# VPE_VPDMA register map
Vendor: Texas Instruments
Registers are 32-bit, access per field, reset 0x0 unless marked. A register's access mark holds for its fields unless they carry their own. Offsets are as the file gives them; [hi:lo] are bit positions; {n}, {i} and the like mark numbered series; 'fields as' and 'values as' point back to an identical list.

## VPE_VPDMA (part 3 of 3)
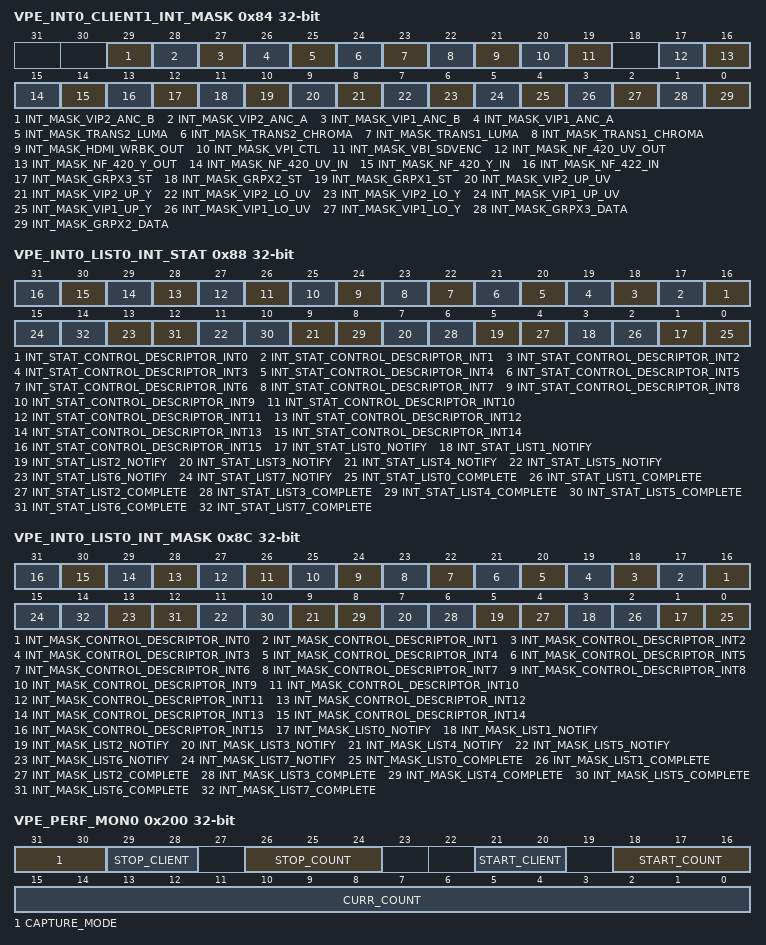
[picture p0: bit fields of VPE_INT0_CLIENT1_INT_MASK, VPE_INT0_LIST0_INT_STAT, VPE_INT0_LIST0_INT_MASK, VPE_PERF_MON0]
0x84 VPE_INT0_CLIENT1_INT_MASK — The register gives the information of the interrupts that should be masked and not generate an interrupt for vpdma_int0.
  [29] INT_MASK_VIP2_ANC_B rw — The interrupt for should generate an interrupt on interrupt vpdma_int0. Write a 1 for the interrupt event to trigger the interrupt signal.
  [28] INT_MASK_VIP2_ANC_A rw — The interrupt for should generate an interrupt on interrupt vpdma_int0. Write a 1 for the interrupt event to trigger the interrupt signal.
  [27] INT_MASK_VIP1_ANC_B rw — The interrupt for should generate an interrupt on interrupt vpdma_int0. Write a 1 for the interrupt event to trigger the interrupt signal.
  [26] INT_MASK_VIP1_ANC_A rw — The interrupt for should generate an interrupt on interrupt vpdma_int0. Write a 1 for the interrupt event to trigger the interrupt signal.
  [25] INT_MASK_TRANS2_LUMA rw — The interrupt for should generate an interrupt on interrupt vpdma_int0. Write a 1 for the interrupt event to trigger the interrupt signal.
  [24] INT_MASK_TRANS2_CHROMA rw — The interrupt for should generate an interrupt on interrupt vpdma_int0. Write a 1 for the interrupt event to trigger the interrupt signal.
  [23] INT_MASK_TRANS1_LUMA rw — The interrupt for should generate an interrupt on interrupt vpdma_int0. Write a 1 for the interrupt event to trigger the interrupt signal.
  [22] INT_MASK_TRANS1_CHROMA rw — The interrupt for should generate an interrupt on interrupt vpdma_int0. Write a 1 for the interrupt event to trigger the interrupt signal.
  [21] INT_MASK_HDMI_WRBK_OUT rw — The interrupt for should generate an interrupt on interrupt vpdma_int0. Write a 1 for the interrupt event to trigger the interrupt signal.
  [20] INT_MASK_VPI_CTL rw — The interrupt for should generate an interrupt on interrupt vpdma_int0. Write a 1 for the interrupt event to trigger the interrupt signal.
  [19] INT_MASK_VBI_SDVENC rw — The interrupt for should generate an interrupt on interrupt vpdma_int0. Write a 1 for the interrupt event to trigger the interrupt signal.
  [17] INT_MASK_NF_420_UV_OUT rw — The interrupt for should generate an interrupt on interrupt vpdma_int0. Write a 1 for the interrupt event to trigger the interrupt signal.
  [16] INT_MASK_NF_420_Y_OUT rw — The interrupt for should generate an interrupt on interrupt vpdma_int0. Write a 1 for the interrupt event to trigger the interrupt signal.
  [15] INT_MASK_NF_420_UV_IN rw — The interrupt for should generate an interrupt on interrupt vpdma_int0. Write a 1 for the interrupt event to trigger the interrupt signal.
  [14] INT_MASK_NF_420_Y_IN rw — The interrupt for should generate an interrupt on interrupt vpdma_int0. Write a 1 for the interrupt event to trigger the interrupt signal.
  [13] INT_MASK_NF_422_IN rw — The interrupt for should generate an interrupt on interrupt vpdma_int0. Write a 1 for the interrupt event to trigger the interrupt signal.
  [12] INT_MASK_GRPX3_ST rw — The interrupt for should generate an interrupt on interrupt vpdma_int0. Write a 1 for the interrupt event to trigger the interrupt signal.
  [11] INT_MASK_GRPX2_ST rw — The interrupt for should generate an interrupt on interrupt vpdma_int0. Write a 1 for the interrupt event to trigger the interrupt signal.
  [10] INT_MASK_GRPX1_ST rw — The interrupt for should generate an interrupt on interrupt vpdma_int0. Write a 1 for the interrupt event to trigger the interrupt signal.
  [9] INT_MASK_VIP2_UP_UV rw — The interrupt for should generate an interrupt on interrupt vpdma_int0. Write a 1 for the interrupt event to trigger the interrupt signal.
  [8] INT_MASK_VIP2_UP_Y rw — The interrupt for should generate an interrupt on interrupt vpdma_int0. Write a 1 for the interrupt event to trigger the interrupt signal.
  [7] INT_MASK_VIP2_LO_UV rw — The interrupt for should generate an interrupt on interrupt vpdma_int0. Write a 1 for the interrupt event to trigger the interrupt signal.
  [6] INT_MASK_VIP2_LO_Y rw — The interrupt for should generate an interrupt on interrupt vpdma_int0. Write a 1 for the interrupt event to trigger the interrupt signal.
  [5] INT_MASK_VIP1_UP_UV rw — The interrupt for should generate an interrupt on interrupt vpdma_int0. Write a 1 for the interrupt event to trigger the interrupt signal.
  [4] INT_MASK_VIP1_UP_Y rw — The interrupt for should generate an interrupt on interrupt vpdma_int0. Write a 1 for the interrupt event to trigger the interrupt signal.
  [3] INT_MASK_VIP1_LO_UV rw — The interrupt for should generate an interrupt on interrupt vpdma_int0. Write a 1 for the interrupt event to trigger the interrupt signal.
  [2] INT_MASK_VIP1_LO_Y rw — The interrupt for should generate an interrupt on interrupt vpdma_int0. Write a 1 for the interrupt event to trigger the interrupt signal.
  [1] INT_MASK_GRPX3_DATA rw — The interrupt for should generate an interrupt on interrupt vpdma_int0. Write a 1 for the interrupt event to trigger the interrupt signal.
  [0] INT_MASK_GRPX2_DATA rw — The interrupt for should generate an interrupt on interrupt vpdma_int0. Write a 1 for the interrupt event to trigger the interrupt signal.
0x88 VPE_INT0_LIST0_INT_STAT rw — This register gives the information of the interrupts that have triggered since last cleared by the process that is servicing vpdma_int0.
  [n+16] INT_STAT_CONTROL_DESCRIPTOR_INT{n} (n=0..15) — A Send Interrupt Control Descriptor has been received by the list manager with a source value of {n}. This event will cause a one to be set in this register until cleared by software. Write a 1 to this field to clear the value.
  [2n+1] INT_STAT_LIST{n}_NOTIFY (n=0..7) — A channel set by List {n} has completed and the Notify bit had been set in the descriptor for that channel. This event will cause a one to be set in this register until cleared by software. Write a 1 to this field to clear the value.
  [2n] INT_STAT_LIST{n}_COMPLETE (n=0..7) — List {n} has completed and a new list can be loaded. This event will cause a one to be set in this register until cleared by software. Write a 1 to this field to clear the value.
0x8C VPE_INT0_LIST0_INT_MASK rw — The register gives the information of the interrupts that should be masked and not generate an interrupt for vpdma_int0.
  [n+16] INT_MASK_CONTROL_DESCRIPTOR_INT{n} (n=0..15) — The interrupt for should generate an interrupt on interrupt vpdma_int0. Write a 1 for the interrupt event to trigger the interrupt signal.
  [2n+1] INT_MASK_LIST{n}_NOTIFY (n=0..7) — The interrupt for should generate an interrupt on interrupt vpdma_int0. Write a 1 for the interrupt event to trigger the interrupt signal.
  [2n] INT_MASK_LIST{n}_COMPLETE (n=0..7) — The interrupt for should generate an interrupt on interrupt vpdma_int0. Write a 1 for the interrupt event to trigger the interrupt signal.
0x200 VPE_PERF_MON0 — The register can be used to capture timing differences between events in the VPDMA
  [31:30] CAPTURE_MODE rw — Sets how the counter should be updated. Updating this value will also clear the current counter stored value.
    0=Running_Average; 1=Minimum_Value; 2=Maximum_Value; 3=Last_Value
  [29:28] STOP_CLIENT rw — Sets the client whose event stops the performance monitor counter.
    0=dei_hq_1_chroma; 1=vpi_ctl; 2=dei_hq_1_luma; 3=dei_hq_2_luma
  [26:24] STOP_COUNT rw — Sets the value that stops the performance monitor counter.
    0=command_request; 1=command_accept; 2=data_request; 3=data_rcvd; 4=data_empty; 5=data_full; 6=frame_start; 7=frame_end
  [21:20] START_CLIENT rw — Sets the client whose event starts the performance monitor counter.
    values as STOP_CLIENT
  [18:16] START_COUNT rw — Sets the value that starts the performance monitor counter.
    values as STOP_COUNT
  [15:0] CURR_COUNT ro — The current value of the perfomance monitor counter
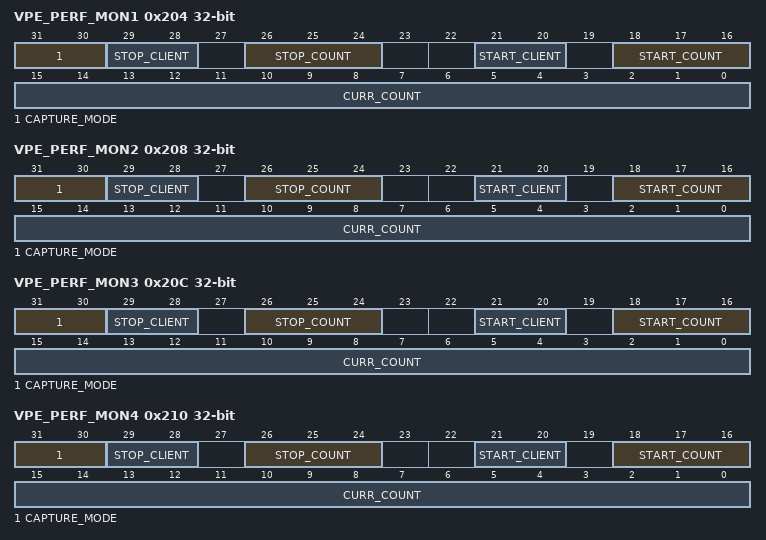
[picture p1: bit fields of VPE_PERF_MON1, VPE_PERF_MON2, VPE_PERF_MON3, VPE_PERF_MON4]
0x204 VPE_PERF_MON1 — The register can be used to capture timing differences between events in the VPDMA
  [31:30] CAPTURE_MODE rw — Sets how the counter should be updated. Updating this value will also clear the current counter stored value.
    values as VPE_PERF_MON0.CAPTURE_MODE
  [29:28] STOP_CLIENT rw — Sets the client whose event stops the performance monitor counter.
    0=dei_hq_1_luma; 1=dei_hq_1_chroma; 2=dei_hq_2_luma; 3=dei_hq_2_chroma
  [26:24] STOP_COUNT rw — Sets the value that stops the performance monitor counter.
    values as VPE_PERF_MON0.STOP_COUNT
  [21:20] START_CLIENT rw — Sets the client whose event starts the performance monitor counter.
    values as STOP_CLIENT
  [18:16] START_COUNT rw — Sets the value that starts the performance monitor counter.
    values as VPE_PERF_MON0.STOP_COUNT
  [15:0] CURR_COUNT ro — The current value of the perfomance monitor counter
0x208 VPE_PERF_MON2 — The register can be used to capture timing differences between events in the VPDMA
  [31:30] CAPTURE_MODE rw — Sets how the counter should be updated. Updating this value will also clear the current counter stored value.
    values as VPE_PERF_MON0.CAPTURE_MODE
  [29:28] STOP_CLIENT rw — Sets the client whose event stops the performance monitor counter.
    0=dei_hq_2_luma; 1=dei_hq_1_luma; 2=dei_hq_2_chroma; 3=dei_hq_3_luma
  [26:24] STOP_COUNT rw — Sets the value that stops the performance monitor counter.
    values as VPE_PERF_MON0.STOP_COUNT
  [21:20] START_CLIENT rw — Sets the client whose event starts the performance monitor counter.
    values as STOP_CLIENT
  [18:16] START_COUNT rw — Sets the value that starts the performance monitor counter.
    values as VPE_PERF_MON0.STOP_COUNT
  [15:0] CURR_COUNT ro — The current value of the perfomance monitor counter
0x20C VPE_PERF_MON3 — The register can be used to capture timing differences between events in the VPDMA
  fields as VPE_PERF_MON2
0x210 VPE_PERF_MON4 — The register can be used to capture timing differences between events in the VPDMA
  [31:30] CAPTURE_MODE rw — Sets how the counter should be updated. Updating this value will also clear the current counter stored value.
    values as VPE_PERF_MON0.CAPTURE_MODE
  [29:28] STOP_CLIENT rw — Sets the client whose event stops the performance monitor counter.
    0=dei_hq_3_luma; 1=dei_hq_2_chroma; 2=dei_hq_3_chroma; 3=STOP_CLIENT_3
  [26:24] STOP_COUNT rw — Sets the value that stops the performance monitor counter.
    values as VPE_PERF_MON0.STOP_COUNT
  [21:20] START_CLIENT rw — Sets the client whose event starts the performance monitor counter.
    0=dei_hq_3_luma; 1=dei_hq_2_chroma; 2=dei_hq_3_chroma; 3=START_CLIENT_3
  [18:16] START_COUNT rw — Sets the value that starts the performance monitor counter.
    values as VPE_PERF_MON0.STOP_COUNT
  [15:0] CURR_COUNT ro — The current value of the perfomance monitor counter
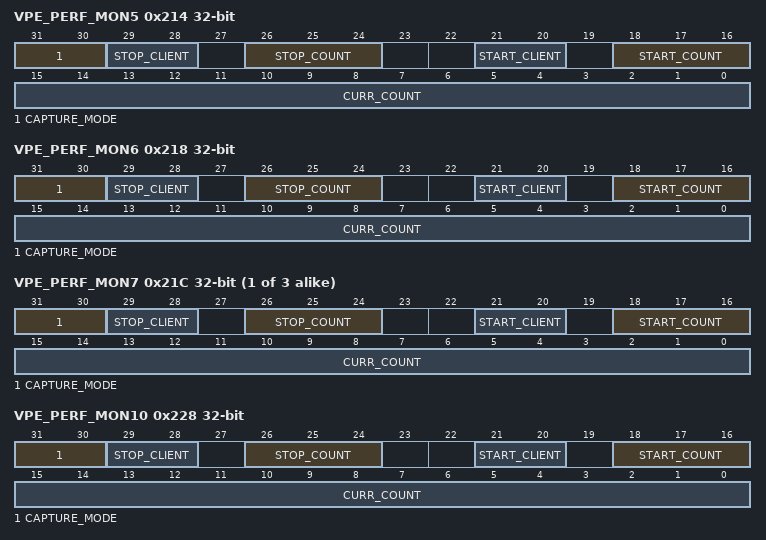
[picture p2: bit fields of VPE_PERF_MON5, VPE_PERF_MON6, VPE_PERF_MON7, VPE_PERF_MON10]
0x214 VPE_PERF_MON5 — The register can be used to capture timing differences between events in the VPDMA
  fields as VPE_PERF_MON4
0x218 VPE_PERF_MON6 — The register can be used to capture timing differences between events in the VPDMA
  [31:30] CAPTURE_MODE rw — Sets how the counter should be updated. Updating this value will also clear the current counter stored value.
    values as VPE_PERF_MON0.CAPTURE_MODE
  [29:28] STOP_CLIENT rw — Sets the client whose event stops the performance monitor counter.
    0=STOP_CLIENT_0; 1=dei_hq_3_chroma; 2=STOP_CLIENT_2; 3=STOP_CLIENT_3
  [26:24] STOP_COUNT rw — Sets the value that stops the performance monitor counter.
    values as VPE_PERF_MON0.STOP_COUNT
  [21:20] START_CLIENT rw — Sets the client whose event starts the performance monitor counter.
    0=dei_hq_3_chroma; 1=dei_hq_3_chroma; 2=START_CLIENT_2; 3=START_CLIENT_3
  [18:16] START_COUNT rw — Sets the value that starts the performance monitor counter.
    values as VPE_PERF_MON0.STOP_COUNT
  [15:0] CURR_COUNT ro — The current value of the perfomance monitor counter
{0x200+4i} VPE_PERF_MON{i} (i=7..9) — The register can be used to capture timing differences between events in the VPDMA
  [31:30] CAPTURE_MODE rw — Sets how the counter should be updated. Updating this value will also clear the current counter stored value.
    values as VPE_PERF_MON0.CAPTURE_MODE
  [29:28] STOP_CLIENT rw — Sets the client whose event stops the performance monitor counter.
  [26:24] STOP_COUNT rw — Sets the value that stops the performance monitor counter.
    values as VPE_PERF_MON0.STOP_COUNT
  [21:20] START_CLIENT rw — Sets the client whose event starts the performance monitor counter.
  [18:16] START_COUNT rw — Sets the value that starts the performance monitor counter.
    values as VPE_PERF_MON0.STOP_COUNT
  [15:0] CURR_COUNT ro — The current value of the perfomance monitor counter
0x228 VPE_PERF_MON10 — The register can be used to capture timing differences between events in the VPDMA
  [31:30] CAPTURE_MODE rw — Sets how the counter should be updated. Updating this value will also clear the current counter stored value.
    values as VPE_PERF_MON0.CAPTURE_MODE
  [29:28] STOP_CLIENT rw — Sets the client whose event stops the performance monitor counter.
    0=STOP_CLIENT_0; 1=STOP_CLIENT_1; 2=STOP_CLIENT_2; 3=dei_hq_mv_in
  [26:24] STOP_COUNT rw — Sets the value that stops the performance monitor counter.
    values as VPE_PERF_MON0.STOP_COUNT
  [21:20] START_CLIENT rw — Sets the client whose event starts the performance monitor counter.
    0=START_CLIENT_0; 1=START_CLIENT_1; 2=START_CLIENT_2; 3=dei_hq_mv_in
  [18:16] START_COUNT rw — Sets the value that starts the performance monitor counter.
    values as VPE_PERF_MON0.STOP_COUNT
  [15:0] CURR_COUNT ro — The current value of the perfomance monitor counter
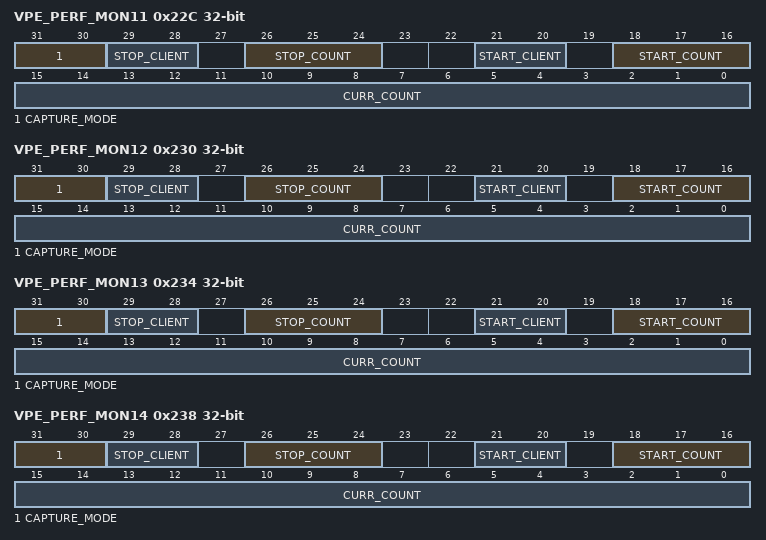
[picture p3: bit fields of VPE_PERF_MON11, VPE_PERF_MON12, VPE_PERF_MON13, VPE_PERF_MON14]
0x22C VPE_PERF_MON11 — The register can be used to capture timing differences between events in the VPDMA
  [31:30] CAPTURE_MODE rw — Sets how the counter should be updated. Updating this value will also clear the current counter stored value.
    values as VPE_PERF_MON0.CAPTURE_MODE
  [29:28] STOP_CLIENT rw — Sets the client whose event stops the performance monitor counter.
    0=STOP_CLIENT_0; 1=STOP_CLIENT_1; 2=dei_hq_mv_in; 3=STOP_CLIENT_3
  [26:24] STOP_COUNT rw — Sets the value that stops the performance monitor counter.
    values as VPE_PERF_MON0.STOP_COUNT
  [21:20] START_CLIENT rw — Sets the client whose event starts the performance monitor counter.
    0=START_CLIENT_0; 1=START_CLIENT_1; 2=dei_hq_mv_in; 3=START_CLIENT_3
  [18:16] START_COUNT rw — Sets the value that starts the performance monitor counter.
    values as VPE_PERF_MON0.STOP_COUNT
  [15:0] CURR_COUNT ro — The current value of the perfomance monitor counter
0x230 VPE_PERF_MON12 — The register can be used to capture timing differences between events in the VPDMA
  [31:30] CAPTURE_MODE rw — Sets how the counter should be updated. Updating this value will also clear the current counter stored value.
    values as VPE_PERF_MON0.CAPTURE_MODE
  [29:28] STOP_CLIENT rw — Sets the client whose event stops the performance monitor counter.
    0=dei_hq_mv_in; 1=STOP_CLIENT_1; 2=STOP_CLIENT_2; 3=STOP_CLIENT_3
  [26:24] STOP_COUNT rw — Sets the value that stops the performance monitor counter.
    values as VPE_PERF_MON0.STOP_COUNT
  [21:20] START_CLIENT rw — Sets the client whose event starts the performance monitor counter.
    0=dei_hq_mv_in; 1=START_CLIENT_1; 2=START_CLIENT_2; 3=START_CLIENT_3
  [18:16] START_COUNT rw — Sets the value that starts the performance monitor counter.
    values as VPE_PERF_MON0.STOP_COUNT
  [15:0] CURR_COUNT ro — The current value of the perfomance monitor counter
0x234 VPE_PERF_MON13 — The register can be used to capture timing differences between events in the VPDMA
  [31:30] CAPTURE_MODE rw — Sets how the counter should be updated. Updating this value will also clear the current counter stored value.
    values as VPE_PERF_MON0.CAPTURE_MODE
  [29:28] STOP_CLIENT rw — Sets the client whose event stops the performance monitor counter.
    0=STOP_CLIENT_0; 1=dei_hq_mv_in; 2=STOP_CLIENT_2; 3=dei_hq_mv_out
  [26:24] STOP_COUNT rw — Sets the value that stops the performance monitor counter.
    values as VPE_PERF_MON0.STOP_COUNT
  [21:20] START_CLIENT rw — Sets the client whose event starts the performance monitor counter.
    0=START_CLIENT_0; 1=dei_hq_mv_in; 2=START_CLIENT_2; 3=dei_hq_mv_out
  [18:16] START_COUNT rw — Sets the value that starts the performance monitor counter.
    values as VPE_PERF_MON0.STOP_COUNT
  [15:0] CURR_COUNT ro — The current value of the perfomance monitor counter
0x238 VPE_PERF_MON14 — The register can be used to capture timing differences between events in the VPDMA
  [31:30] CAPTURE_MODE rw — Sets how the counter should be updated. Updating this value will also clear the current counter stored value.
    values as VPE_PERF_MON0.CAPTURE_MODE
  [29:28] STOP_CLIENT rw — Sets the client whose event stops the performance monitor counter.
    0=STOP_CLIENT_0; 1=STOP_CLIENT_1; 2=dei_hq_mv_out; 3=STOP_CLIENT_3
  [26:24] STOP_COUNT rw — Sets the value that stops the performance monitor counter.
    values as VPE_PERF_MON0.STOP_COUNT
  [21:20] START_CLIENT rw — Sets the client whose event starts the performance monitor counter.
    0=START_CLIENT_0; 1=START_CLIENT_1; 2=dei_hq_mv_out; 3=START_CLIENT_3
  [18:16] START_COUNT rw — Sets the value that starts the performance monitor counter.
    values as VPE_PERF_MON0.STOP_COUNT
  [15:0] CURR_COUNT ro — The current value of the perfomance monitor counter
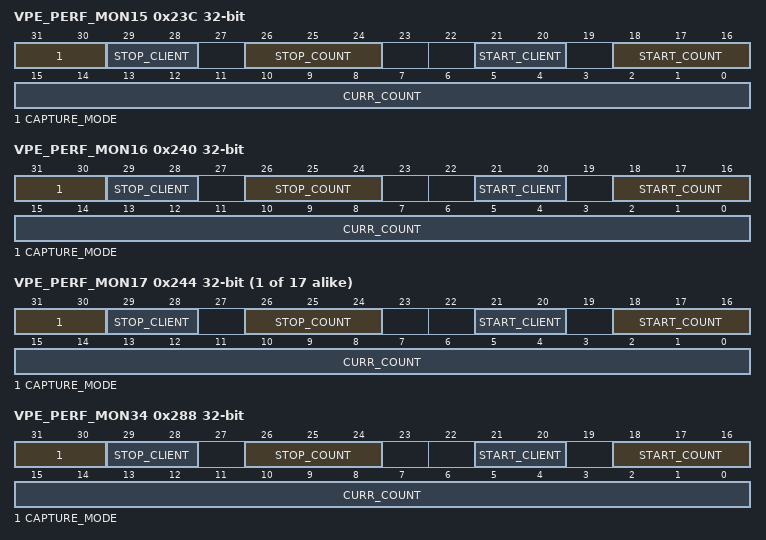
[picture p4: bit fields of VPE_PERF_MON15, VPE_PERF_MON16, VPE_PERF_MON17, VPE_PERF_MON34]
0x23C VPE_PERF_MON15 — The register can be used to capture timing differences between events in the VPDMA
  [31:30] CAPTURE_MODE rw — Sets how the counter should be updated. Updating this value will also clear the current counter stored value.
    values as VPE_PERF_MON0.CAPTURE_MODE
  [29:28] STOP_CLIENT rw — Sets the client whose event stops the performance monitor counter.
    0=dei_hq_mv_out; 1=STOP_CLIENT_1; 2=STOP_CLIENT_2; 3=STOP_CLIENT_3
  [26:24] STOP_COUNT rw — Sets the value that stops the performance monitor counter.
    values as VPE_PERF_MON0.STOP_COUNT
  [21:20] START_CLIENT rw — Sets the client whose event starts the performance monitor counter.
    0=dei_hq_mv_out; 1=START_CLIENT_1; 2=START_CLIENT_2; 3=START_CLIENT_3
  [18:16] START_COUNT rw — Sets the value that starts the performance monitor counter.
    values as VPE_PERF_MON0.STOP_COUNT
  [15:0] CURR_COUNT ro — The current value of the perfomance monitor counter
0x240 VPE_PERF_MON16 — The register can be used to capture timing differences between events in the VPDMA
  [31:30] CAPTURE_MODE rw — Sets how the counter should be updated. Updating this value will also clear the current counter stored value.
    values as VPE_PERF_MON0.CAPTURE_MODE
  [29:28] STOP_CLIENT rw — Sets the client whose event stops the performance monitor counter.
    0=STOP_CLIENT_0; 1=dei_hq_mv_out; 2=STOP_CLIENT_2; 3=STOP_CLIENT_3
  [26:24] STOP_COUNT rw — Sets the value that stops the performance monitor counter.
    values as VPE_PERF_MON0.STOP_COUNT
  [21:20] START_CLIENT rw — Sets the client whose event starts the performance monitor counter.
    0=START_CLIENT_0; 1=dei_hq_mv_out; 2=START_CLIENT_2; 3=START_CLIENT_3
  [18:16] START_COUNT rw — Sets the value that starts the performance monitor counter.
    values as VPE_PERF_MON0.STOP_COUNT
  [15:0] CURR_COUNT ro — The current value of the perfomance monitor counter
{0x200+4i} VPE_PERF_MON{i} (i=17..33) — The register can be used to capture timing differences between events in the VPDMA
  fields as VPE_PERF_MON7
0x288 VPE_PERF_MON34 — The register can be used to capture timing differences between events in the VPDMA
  [31:30] CAPTURE_MODE rw — Sets how the counter should be updated. Updating this value will also clear the current counter stored value.
    values as VPE_PERF_MON0.CAPTURE_MODE
  [29:28] STOP_CLIENT rw — Sets the client whose event stops the performance monitor counter.
    0=STOP_CLIENT_0; 1=STOP_CLIENT_1; 2=STOP_CLIENT_2; 3=vip1_up_y
  [26:24] STOP_COUNT rw — Sets the value that stops the performance monitor counter.
    values as VPE_PERF_MON0.STOP_COUNT
  [21:20] START_CLIENT rw — Sets the client whose event starts the performance monitor counter.
    0=START_CLIENT_0; 1=START_CLIENT_1; 2=START_CLIENT_2; 3=vip1_up_y
  [18:16] START_COUNT rw — Sets the value that starts the performance monitor counter.
    values as VPE_PERF_MON0.STOP_COUNT
  [15:0] CURR_COUNT ro — The current value of the perfomance monitor counter
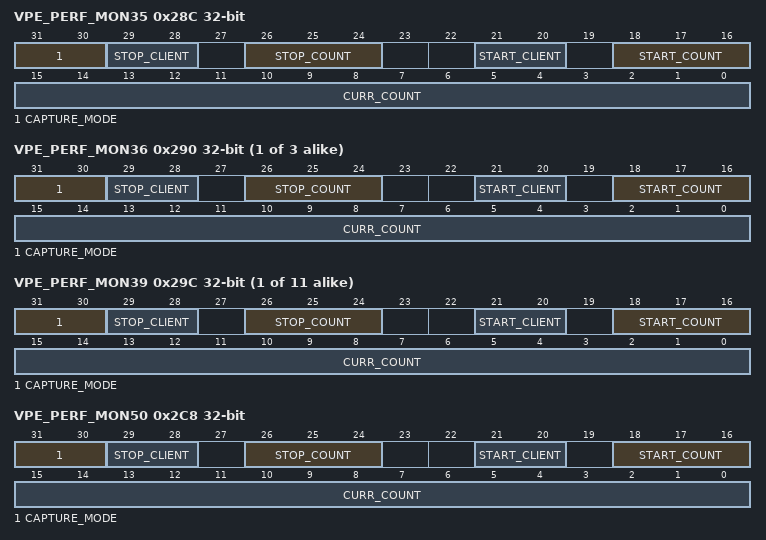
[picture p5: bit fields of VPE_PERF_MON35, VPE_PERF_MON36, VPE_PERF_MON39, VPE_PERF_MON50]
0x28C VPE_PERF_MON35 — The register can be used to capture timing differences between events in the VPDMA
  [31:30] CAPTURE_MODE rw — Sets how the counter should be updated. Updating this value will also clear the current counter stored value.
    values as VPE_PERF_MON0.CAPTURE_MODE
  [29:28] STOP_CLIENT rw — Sets the client whose event stops the performance monitor counter.
    0=STOP_CLIENT_0; 1=STOP_CLIENT_1; 2=vip1_up_y; 3=vip1_up_uv
  [26:24] STOP_COUNT rw — Sets the value that stops the performance monitor counter.
    values as VPE_PERF_MON0.STOP_COUNT
  [21:20] START_CLIENT rw — Sets the client whose event starts the performance monitor counter.
    0=START_CLIENT_0; 1=START_CLIENT_1; 2=vip1_up_y; 3=vip1_up_uv
  [18:16] START_COUNT rw — Sets the value that starts the performance monitor counter.
    values as VPE_PERF_MON0.STOP_COUNT
  [15:0] CURR_COUNT ro — The current value of the perfomance monitor counter
{0x200+4i} VPE_PERF_MON{i} (i=36..38) — The register can be used to capture timing differences between events in the VPDMA
  [31:30] CAPTURE_MODE rw — Sets how the counter should be updated. Updating this value will also clear the current counter stored value.
    values as VPE_PERF_MON0.CAPTURE_MODE
  [29:28] STOP_CLIENT rw — Sets the client whose event stops the performance monitor counter.
    0=vip1_up_uv; 1=vip1_up_y; 2=STOP_CLIENT_2; 3=STOP_CLIENT_3
  [26:24] STOP_COUNT rw — Sets the value that stops the performance monitor counter.
    values as VPE_PERF_MON0.STOP_COUNT
  [21:20] START_CLIENT rw — Sets the client whose event starts the performance monitor counter.
    0=vip1_up_uv; 1=vip1_up_y; 2=START_CLIENT_2; 3=START_CLIENT_3
  [18:16] START_COUNT rw — Sets the value that starts the performance monitor counter.
    values as VPE_PERF_MON0.STOP_COUNT
  [15:0] CURR_COUNT ro — The current value of the perfomance monitor counter
{0x200+4i} VPE_PERF_MON{i} (i=39..49) — The register can be used to capture timing differences between events in the VPDMA
  [31:30] CAPTURE_MODE rw — Sets how the counter should be updated. Updating this value will also clear the current counter stored value. 0: Running Average 1: Minimum Value 2: Maximum Value 3: Last Value
    values as VPE_PERF_MON0.CAPTURE_MODE
  [29:28] STOP_CLIENT rw — Sets the client whose event stops the performance monitor counter.
  [26:24] STOP_COUNT rw — Sets the value that stops the performance monitor counter.
    values as VPE_PERF_MON0.STOP_COUNT
  [21:20] START_CLIENT rw — Sets the client whose event starts the performance monitor counter.
  [18:16] START_COUNT rw — Sets the value that starts the performance monitor counter.
    values as VPE_PERF_MON0.STOP_COUNT
  [15:0] CURR_COUNT ro — The current value of the perfomance monitor counter
0x2C8 VPE_PERF_MON50 — The register can be used to capture timing differences between events in the VPDMA
  [31:30] CAPTURE_MODE rw — Sets how the counter should be updated. Updating this value will also clear the current counter stored value.
    values as VPE_PERF_MON0.CAPTURE_MODE
  [29:28] STOP_CLIENT rw — Sets the client whose event stops the performance monitor counter.
    {v}=vpi_ctl (v=0..3)
  [26:24] STOP_COUNT rw — Sets the value that stops the performance monitor counter.
    values as VPE_PERF_MON0.STOP_COUNT
  [21:20] START_CLIENT rw — Sets the client whose event starts the performance monitor counter.
    {v}=vpi_ctl (v=0..3)
  [18:16] START_COUNT rw — Sets the value that starts the performance monitor counter.
    values as VPE_PERF_MON0.STOP_COUNT
  [15:0] CURR_COUNT ro — The current value of the perfomance monitor counter
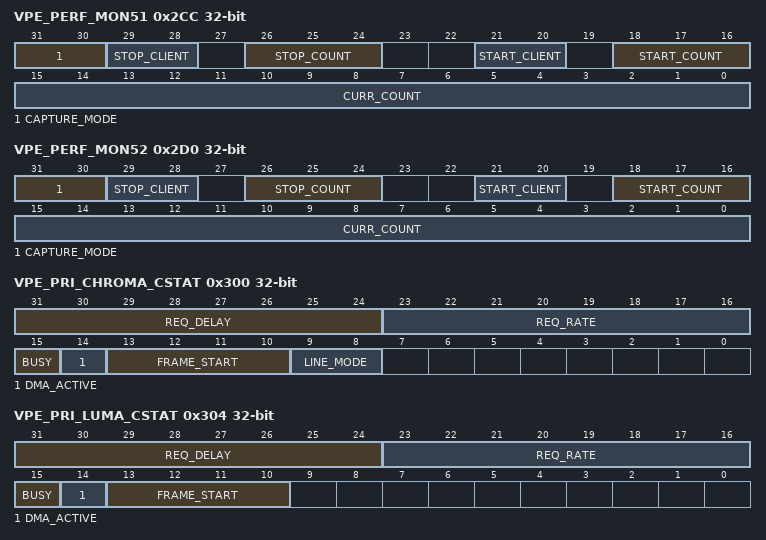
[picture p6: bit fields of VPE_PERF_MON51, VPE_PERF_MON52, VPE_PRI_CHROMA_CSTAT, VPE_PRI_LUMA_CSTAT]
0x2CC VPE_PERF_MON51 — The register can be used to capture timing differences between events in the VPDMA
  [31:30] CAPTURE_MODE rw — Sets how the counter should be updated. Updating this value will also clear the current counter stored value.
    values as VPE_PERF_MON0.CAPTURE_MODE
  [29:28] STOP_CLIENT rw — Sets the client whose event stops the performance monitor counter.
    0=vpi_ctl; 1=dei_hq_1_chroma; 2=dei_hq_1_chroma; 3=dei_hq_1_luma
  [26:24] STOP_COUNT rw — Sets the value that stops the performance monitor counter.
    values as VPE_PERF_MON0.STOP_COUNT
  [21:20] START_CLIENT rw — Sets the client whose event starts the performance monitor counter.
    values as STOP_CLIENT
  [18:16] START_COUNT rw — Sets the value that starts the performance monitor counter.
    values as VPE_PERF_MON0.STOP_COUNT
  [15:0] CURR_COUNT ro — The current value of the perfomance monitor counter
0x2D0 VPE_PERF_MON52 — The register can be used to capture timing differences between events in the VPDMA
  fields as VPE_PERF_MON51
0x300 VPE_PRI_CHROMA_CSTAT — The register holds status information and control for the client.
  [31:24] REQ_DELAY rw — The minimum number of clock cycles between requests being issued. This value is multiplied by 32 to get the actual number of cycles..This value is only accurate for the current frame. The internal counters used to calculate the rate are reset when a new frame begins and the first request of a frame will go as soon as possible.
  [23:16] REQ_RATE ro — The number of clock cycles between the last two requests issued. This value is multiplied by 32 to get the actual number of cycles.This value is only accurate for the current frame. The internal counters used to calculate the rate are reset when a new frame begins.
  [15] BUSY ro — Signals if the client is currently active. This bit is set as soon as we the channel is received by the client from the list manager and is cleared when the channel is cleared from the shared memory.
  [14] DMA_ACTIVE ro — Signals if the client is currently actively sending DMA requests
  [13:10] FRAME_START rw — The source of the start frame event for the client.
    0=Change_in_value_of_hdmi_field_id; 1=Change_in_value_of_dvo2_field_id; 2=Change_in_value_of_hdcomp_field_id; 3=Change_in_value_of_sd_field_id; 4=Use_List_Manager_Internal_Field0; 5=Use_List_Manager_Internal_Field1; 6=Use_List_Manager_Internal_Field2; 7=Start_on_channel_active
  [9:8] LINE_MODE rw — Selects the output mode of the line buffer.
    0=repeat lines twice each output data line gets 2 times the number of frame lines; 1=each line once with Line Buffer Disabled, so no mirroring. Each line gets frame lines with identical data.; 2=Each line seen once Mirroring is enabled so the top lines get the top lines repeated at the top of the frame and the bottom lines have the bottom lines repeated. Each line of data gets frame lines + number of buffered lines.; 3=each line once only on one line. Each data line gets number of frame lines divided by number of buffered lines.
0x304 VPE_PRI_LUMA_CSTAT — The register holds status information and control for the client.
  [31:24] REQ_DELAY rw — The minimum number of clock cycles between requests being issued. This value is multiplied by 32 to get the actual number of cycles..This value is only accurate for the current frame. The internal counters used to calculate the rate are reset when a new frame begins and the first request of a frame will go as soon as possible.
  [23:16] REQ_RATE ro — The number of clock cycles between the last two requests issued. This value is multiplied by 32 to get the actual number of cycles.This value is only accurate for the current frame. The internal counters used to calculate the rate are reset when a new frame begins.
  [15] BUSY ro — Signals if the client is currently active. This bit is set as soon as we the channel is received by the client from the list manager and is cleared when the channel is cleared from the shared memory.
  [14] DMA_ACTIVE ro — Signals if the client is currently actively sending DMA requests
  [13:10] FRAME_START rw — The source of the start frame event for the client.
    values as VPE_PRI_CHROMA_CSTAT.FRAME_START
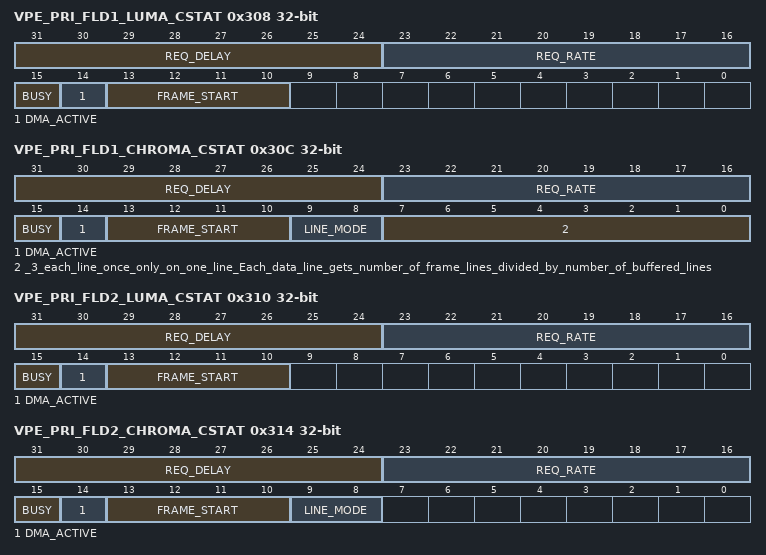
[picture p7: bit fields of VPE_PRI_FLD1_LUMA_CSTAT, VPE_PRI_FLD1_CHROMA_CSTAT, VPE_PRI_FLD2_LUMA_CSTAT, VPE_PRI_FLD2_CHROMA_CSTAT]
0x308 VPE_PRI_FLD1_LUMA_CSTAT — The register holds status information and control for the client.
  fields as VPE_PRI_LUMA_CSTAT
0x30C VPE_PRI_FLD1_CHROMA_CSTAT — The register holds status information and control for the client.
  [31:24] REQ_DELAY rw — The minimum number of clock cycles between requests being issued. This value is multiplied by 32 to get the actual number of cycles..This value is only accurate for the current frame. The internal counters used to calculate the rate are reset when a new frame begins and the first request of a frame will go as soon as possible.
  [23:16] REQ_RATE ro — The number of clock cycles between the last two requests issued. This value is multiplied by 32 to get the actual number of cycles.This value is only accurate for the current frame. The internal counters used to calculate the rate are reset when a new frame begins.
  [15] BUSY ro — Signals if the client is currently active. This bit is set as soon as we the channel is received by the client from the list manager and is cleared when the channel is cleared from the shared memory.
  [14] DMA_ACTIVE ro — Signals if the client is currently actively sending DMA requests
  [13:10] FRAME_START rw — The source of the start frame event for the client.
    values as VPE_PRI_CHROMA_CSTAT.FRAME_START
  [9:8] LINE_MODE rw — Selects the output mode of the line buffer.
    values as VPE_PRI_CHROMA_CSTAT.LINE_MODE
  [7:0] _3_each_line_once_only_on_one_line_Each_data_line_gets_number_of_frame_lines_divided_by_number_of_buffered_lines ro
0x310 VPE_PRI_FLD2_LUMA_CSTAT — The register holds status information and control for the client.
  fields as VPE_PRI_LUMA_CSTAT
0x314 VPE_PRI_FLD2_CHROMA_CSTAT — The register holds status information and control for the client.
  fields as VPE_PRI_CHROMA_CSTAT
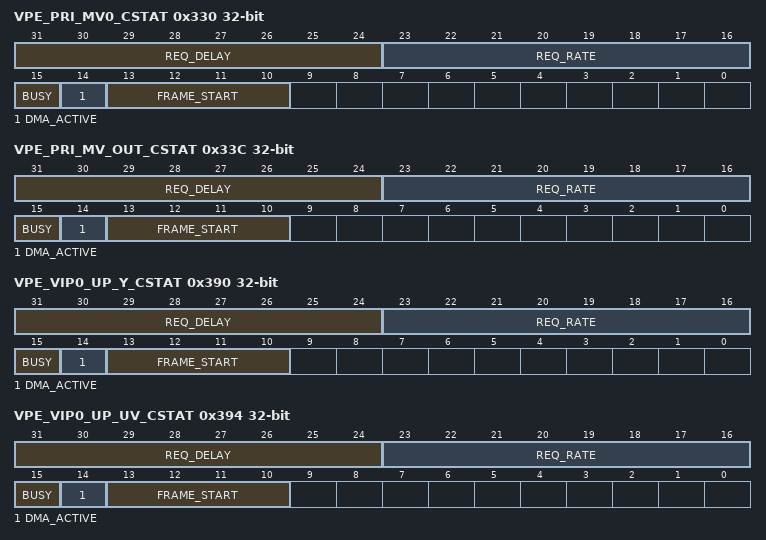
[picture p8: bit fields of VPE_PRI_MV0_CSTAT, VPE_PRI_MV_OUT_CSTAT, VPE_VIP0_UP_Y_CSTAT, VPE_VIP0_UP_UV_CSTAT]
0x330 VPE_PRI_MV0_CSTAT — The register holds status information and control for the client.
  fields as VPE_PRI_LUMA_CSTAT
0x33C VPE_PRI_MV_OUT_CSTAT — The register holds status information and control for the client.
  [31:24] REQ_DELAY rw — The minimum number of clock cycles between requests being issued. This value is multiplied by 32 to get the actual number of cycles.This value is only accurate for the current frame. The internal counters used to calculate the rate are reset when a new frame begins and the first request of a frame will go as soon as possible.
  [23:16] REQ_RATE ro — The number of clock cycles between the last two requests issued. This value is multiplied by 32 to get the actual number of cycles.This value is only accurate for the current frame. The internal counters used to calculate the rate are reset when a new frame begins.
  [15] BUSY ro — Signals if the client is currently active. This bit is set as soon as we the channel is received by the client from the list manager and is cleared when the channel is cleared from the shared memory.
  [14] DMA_ACTIVE ro — Signals if the client is currently actively sending DMA requests
  [13:10] FRAME_START rw — The source of the start frame event for the client.
    values as VPE_PRI_CHROMA_CSTAT.FRAME_START
0x390 VPE_VIP0_UP_Y_CSTAT — The register holds status information and control for the client.
  [31:24] REQ_DELAY rw — The minimum number of clock cycles between requests being issued. This value is multiplied by 32 to get the actual number of cycles..This value is only accurate for the current frame. The internal counters used to calculate the rate are reset when a new frame begins and the first request of a frame will go as soon as possible.
  [23:16] REQ_RATE ro — The number of clock cycles between the last two requests issued. This value is multiplied by 32 to get the actual number of cycles.This value is only accurate for the current frame. The internal counters used to calculate the rate are reset when a new frame begins.
  [15] BUSY ro — Signals if the client is currently active. This bit is set as soon as we the channel is received by the client from the list manager and is cleared when the channel is cleared from the shared memory.
  [14] DMA_ACTIVE ro — Signals if the client is currently actively sending DMA requests
  [13:10] FRAME_START rw — The source of the start frame event for the client
    values as VPE_PRI_CHROMA_CSTAT.FRAME_START
0x394 VPE_VIP0_UP_UV_CSTAT — The register holds status information and control for the client.
  fields as VPE_PRI_LUMA_CSTAT
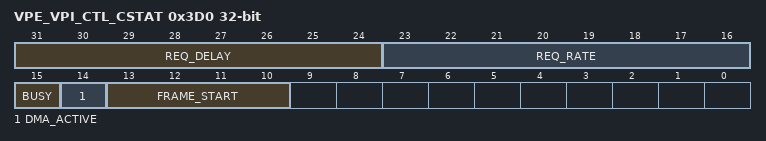
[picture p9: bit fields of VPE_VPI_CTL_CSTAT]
0x3D0 VPE_VPI_CTL_CSTAT — The register holds status information and control for the client.
  fields as VPE_PRI_LUMA_CSTAT
